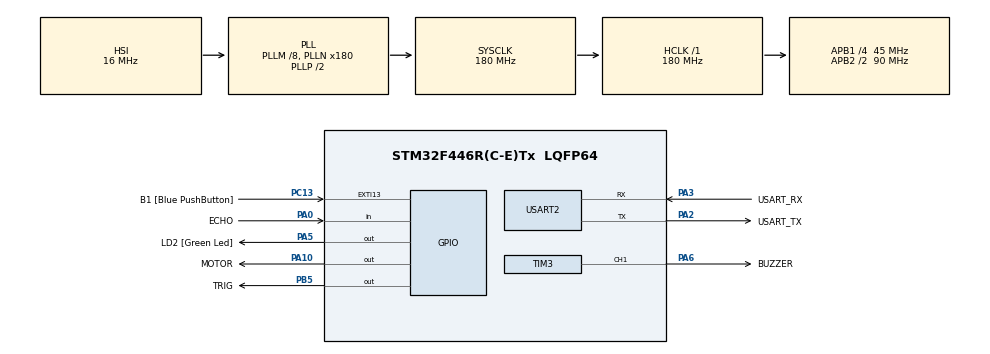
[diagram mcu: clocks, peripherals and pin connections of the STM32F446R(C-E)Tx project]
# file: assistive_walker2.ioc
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FREERTOS.Tasks01=defaultTask,24,128,StartDefaultTask,Default,NULL,Dynamic,NULL,NULL
Mcu.Family=STM32F4
Mcu.Name=STM32F446R(C-E)Tx
Mcu.Package=LQFP64
NVIC.PriorityGroup=NVIC_PRIORITYGROUP_4
NVIC.TIM6_DAC_IRQn=true\:15\:0\:false\:false\:true\:false\:false\:true\:true
NVIC.TimeBase=TIM6_DAC_IRQn
NVIC.TimeBaseIP=TIM6
PA0-WKUP.GPIO_Label=ECHO
PA0-WKUP.Signal=GPIO_Input
PA10.GPIO_Label=MOTOR
PA10.Signal=GPIO_Output
PA13.GPIO_Label=TMS
PA13.Mode=Serial_Wire
PA13.Signal=SYS_JTMS-SWDIO
PA14.GPIO_Label=TCK
PA14.Mode=Serial_Wire
PA14.Signal=SYS_JTCK-SWCLK
PA2.GPIO_Label=USART_TX
PA2.Mode=Asynchronous
PA2.Signal=USART2_TX
PA3.GPIO_Label=USART_RX
PA3.Mode=Asynchronous
PA3.Signal=USART2_RX
PA5.GPIO_Label=LD2 [Green Led]
PA5.Signal=GPIO_Output
PA6.GPIO_Label=BUZZER
PA6.Signal=S_TIM3_CH1
PB3.GPIO_Label=SWO
PB3.Signal=SYS_JTDO-SWO
PB5.GPIO_Label=TRIG
PB5.Signal=GPIO_Output
PC13.GPIO_Label=B1 [Blue PushButton]
PC13.GPIO_ModeDefaultEXTI=GPIO_MODE_IT_FALLING
PC13.Signal=GPXTI13
PC14-OSC32_IN.Mode=LSE-External-Oscillator
PC14-OSC32_IN.Signal=RCC_OSC32_IN
PC15-OSC32_OUT.Mode=LSE-External-Oscillator
PC15-OSC32_OUT.Signal=RCC_OSC32_OUT
PH0-OSC_IN.Mode=HSE-External-Oscillator
PH0-OSC_IN.Signal=RCC_OSC_IN
PH1-OSC_OUT.Mode=HSE-External-Oscillator
PH1-OSC_OUT.Signal=RCC_OSC_OUT
ProjectManager.HeapSize=0x200
ProjectManager.StackSize=0x400
ProjectManager.TargetToolchain=STM32CubeIDE
RCC.48MHZClocksFreq_Value=84000000
RCC.AHBFreq_Value=180000000
RCC.APB1CLKDivider=RCC_HCLK_DIV4
RCC.APB1Freq_Value=45000000
RCC.APB1TimFreq_Value=90000000
RCC.APB2CLKDivider=RCC_HCLK_DIV2
RCC.APB2Freq_Value=90000000
RCC.APB2TimFreq_Value=180000000
RCC.CortexFreq_Value=180000000
RCC.FLatency-AdvancedSettings=FLASH_LATENCY_5
RCC.HCLKFreq_Value=180000000
RCC.HSE_VALUE=8000000
RCC.HSI_VALUE=16000000
RCC.PLLM=8
RCC.PLLN=180
RCC.SYSCLKFreq_VALUE=180000000
RCC.SYSCLKSource=RCC_SYSCLKSOURCE_PLLCLK
RCC.USBFreq_Value=180000000
RCC.VCOOutputFreq_Value=360000000
SH.S_TIM3_CH1.0=TIM3_CH1,PWM Generation1 CH1
TIM3.Channel-PWM\ Generation1\ CH1=TIM_CHANNEL_1
TIM3.Period=499
TIM3.Prescaler=89
TIM3.Pulse-PWM\ Generation1\ CH1=250
USART2.VirtualMode=VM_ASYNC
VP_FREERTOS_VS_CMSIS_V2.Mode=CMSIS_V2
VP_IWDG_VS_IWDG.Mode=IWDG_Activate
VP_SYS_VS_tim6.Mode=TIM6
board=NUCLEO-F446RE

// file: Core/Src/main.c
/* USER CODE BEGIN Header */
/**
  ******************************************************************************
  * @file           : main.c
  * @brief          : Main program body
  ******************************************************************************
  * @attention
  *
  * Copyright (c) 2026 STMicroelectronics.
  * All rights reserved.
  *
  * This software is licensed under terms that can be found in the LICENSE file
  * in the root directory of this software component.
  * If no LICENSE file comes with this software, it is provided AS-IS.
  *
  ******************************************************************************
  */
/* USER CODE END Header */
#include "main.h"
#include "cmsis_os.h"

IWDG_HandleTypeDef hiwdg;

TIM_HandleTypeDef htim3;

UART_HandleTypeDef huart2;

/* Definitions for defaultTask */
osThreadId_t defaultTaskHandle;
const osThreadAttr_t defaultTask_attributes = {
  .name = "defaultTask",
  .stack_size = 128 * 4,
  .priority = (osPriority_t) osPriorityNormal,
};

void SystemClock_Config(void);
static void MX_GPIO_Init(void);
static void MX_USART2_UART_Init(void);
static void MX_TIM3_Init(void);
static void MX_IWDG_Init(void);
void StartDefaultTask(void *argument);

int main(void)
{

  /* MCU Configuration--------------------------------------------------------*/

  /* Reset of all peripherals, Initializes the Flash interface and the Systick. */
  HAL_Init();

  /* Configure the system clock */
  SystemClock_Config();

  /* Initialize all configured peripherals */
  MX_GPIO_Init();
  MX_USART2_UART_Init();
  MX_TIM3_Init();
  MX_IWDG_Init();

  /* Init scheduler */
  osKernelInitialize();

  /* Create the thread(s) */
  /* creation of defaultTask */
  defaultTaskHandle = osThreadNew(StartDefaultTask, NULL, &defaultTask_attributes);

  /* Start scheduler */
  osKernelStart();

  /* We should never get here as control is now taken by the scheduler */

  /* Infinite loop */
  while (1)
  {

  }
}

void SystemClock_Config(void)
{
  RCC_OscInitTypeDef RCC_OscInitStruct = {0};
  RCC_ClkInitTypeDef RCC_ClkInitStruct = {0};

  /** Configure the main internal regulator output voltage
  */
  __HAL_RCC_PWR_CLK_ENABLE();
  __HAL_PWR_VOLTAGESCALING_CONFIG(PWR_REGULATOR_VOLTAGE_SCALE1);

  /** Initializes the RCC Oscillators according to the specified parameters
  * in the RCC_OscInitTypeDef structure.
  */
  RCC_OscInitStruct.OscillatorType = RCC_OSCILLATORTYPE_HSI|RCC_OSCILLATORTYPE_LSI;
  RCC_OscInitStruct.HSIState = RCC_HSI_ON;
  RCC_OscInitStruct.HSICalibrationValue = RCC_HSICALIBRATION_DEFAULT;
  RCC_OscInitStruct.LSIState = RCC_LSI_ON;
  RCC_OscInitStruct.PLL.PLLState = RCC_PLL_ON;
  RCC_OscInitStruct.PLL.PLLSource = RCC_PLLSOURCE_HSI;
  RCC_OscInitStruct.PLL.PLLM = 8;
  RCC_OscInitStruct.PLL.PLLN = 180;
  RCC_OscInitStruct.PLL.PLLP = RCC_PLLP_DIV2;
  RCC_OscInitStruct.PLL.PLLQ = 2;
  RCC_OscInitStruct.PLL.PLLR = 2;
  if (HAL_RCC_OscConfig(&RCC_OscInitStruct) != HAL_OK)
  {
    Error_Handler();
  }

  /** Activate the Over-Drive mode
  */
  if (HAL_PWREx_EnableOverDrive() != HAL_OK)
  {
    Error_Handler();
  }

  /** Initializes the CPU, AHB and APB buses clocks
  */
  RCC_ClkInitStruct.ClockType = RCC_CLOCKTYPE_HCLK|RCC_CLOCKTYPE_SYSCLK
                              |RCC_CLOCKTYPE_PCLK1|RCC_CLOCKTYPE_PCLK2;
  RCC_ClkInitStruct.SYSCLKSource = RCC_SYSCLKSOURCE_PLLCLK;
  RCC_ClkInitStruct.AHBCLKDivider = RCC_SYSCLK_DIV1;
  RCC_ClkInitStruct.APB1CLKDivider = RCC_HCLK_DIV4;
  RCC_ClkInitStruct.APB2CLKDivider = RCC_HCLK_DIV2;

  if (HAL_RCC_ClockConfig(&RCC_ClkInitStruct, FLASH_LATENCY_5) != HAL_OK)
  {
    Error_Handler();
  }
}

static void MX_IWDG_Init(void)
{

  hiwdg.Instance = IWDG;
  hiwdg.Init.Prescaler = IWDG_PRESCALER_4;
  hiwdg.Init.Reload = 4095;
  if (HAL_IWDG_Init(&hiwdg) != HAL_OK)
  {
    Error_Handler();
  }

}

static void MX_TIM3_Init(void)
{

  TIM_MasterConfigTypeDef sMasterConfig = {0};
  TIM_OC_InitTypeDef sConfigOC = {0};

  htim3.Instance = TIM3;
  htim3.Init.Prescaler = 89;
  htim3.Init.CounterMode = TIM_COUNTERMODE_UP;
  htim3.Init.Period = 499;
  htim3.Init.ClockDivision = TIM_CLOCKDIVISION_DIV1;
  htim3.Init.AutoReloadPreload = TIM_AUTORELOAD_PRELOAD_DISABLE;
  if (HAL_TIM_PWM_Init(&htim3) != HAL_OK)
  {
    Error_Handler();
  }
  sMasterConfig.MasterOutputTrigger = TIM_TRGO_RESET;
  sMasterConfig.MasterSlaveMode = TIM_MASTERSLAVEMODE_DISABLE;
  if (HAL_TIMEx_MasterConfigSynchronization(&htim3, &sMasterConfig) != HAL_OK)
  {
    Error_Handler();
  }
  sConfigOC.OCMode = TIM_OCMODE_PWM1;
  sConfigOC.Pulse = 250;
  sConfigOC.OCPolarity = TIM_OCPOLARITY_HIGH;
  sConfigOC.OCFastMode = TIM_OCFAST_DISABLE;
  if (HAL_TIM_PWM_ConfigChannel(&htim3, &sConfigOC, TIM_CHANNEL_1) != HAL_OK)
  {
    Error_Handler();
  }
  HAL_TIM_MspPostInit(&htim3);

}

static void MX_USART2_UART_Init(void)
{

  huart2.Instance = USART2;
  huart2.Init.BaudRate = 115200;
  huart2.Init.WordLength = UART_WORDLENGTH_8B;
  huart2.Init.StopBits = UART_STOPBITS_1;
  huart2.Init.Parity = UART_PARITY_NONE;
  huart2.Init.Mode = UART_MODE_TX_RX;
  huart2.Init.HwFlowCtl = UART_HWCONTROL_NONE;
  huart2.Init.OverSampling = UART_OVERSAMPLING_16;
  if (HAL_UART_Init(&huart2) != HAL_OK)
  {
    Error_Handler();
  }

}

static void MX_GPIO_Init(void)
{
  GPIO_InitTypeDef GPIO_InitStruct = {0};

  /* GPIO Ports Clock Enable */
  __HAL_RCC_GPIOC_CLK_ENABLE();
  __HAL_RCC_GPIOH_CLK_ENABLE();
  __HAL_RCC_GPIOA_CLK_ENABLE();
  __HAL_RCC_GPIOB_CLK_ENABLE();

  /*Configure GPIO pin Output Level */
  HAL_GPIO_WritePin(GPIOA, LD2_Pin|MOTOR_Pin, GPIO_PIN_RESET);

  /*Configure GPIO pin Output Level */
  HAL_GPIO_WritePin(TRIG_GPIO_Port, TRIG_Pin, GPIO_PIN_RESET);

  /*Configure GPIO pin : B1_Pin */
  GPIO_InitStruct.Pin = B1_Pin;
  GPIO_InitStruct.Mode = GPIO_MODE_IT_FALLING;
  GPIO_InitStruct.Pull = GPIO_NOPULL;
  HAL_GPIO_Init(B1_GPIO_Port, &GPIO_InitStruct);

  /*Configure GPIO pin : ECHO_Pin */
  GPIO_InitStruct.Pin = ECHO_Pin;
  GPIO_InitStruct.Mode = GPIO_MODE_INPUT;
  GPIO_InitStruct.Pull = GPIO_NOPULL;
  HAL_GPIO_Init(ECHO_GPIO_Port, &GPIO_InitStruct);

  /*Configure GPIO pins : LD2_Pin MOTOR_Pin */
  GPIO_InitStruct.Pin = LD2_Pin|MOTOR_Pin;
  GPIO_InitStruct.Mode = GPIO_MODE_OUTPUT_PP;
  GPIO_InitStruct.Pull = GPIO_NOPULL;
  GPIO_InitStruct.Speed = GPIO_SPEED_FREQ_LOW;
  HAL_GPIO_Init(GPIOA, &GPIO_InitStruct);

  /*Configure GPIO pin : TRIG_Pin */
  GPIO_InitStruct.Pin = TRIG_Pin;
  GPIO_InitStruct.Mode = GPIO_MODE_OUTPUT_PP;
  GPIO_InitStruct.Pull = GPIO_NOPULL;
  GPIO_InitStruct.Speed = GPIO_SPEED_FREQ_LOW;
  HAL_GPIO_Init(TRIG_GPIO_Port, &GPIO_InitStruct);

  /* USER CODE BEGIN MX_GPIO_Init_2 */
  GPIO_InitStruct.Pin = ECHO_Pin;
  GPIO_InitStruct.Mode = GPIO_MODE_IT_RISING_FALLING;
  GPIO_InitStruct.Pull = GPIO_NOPULL;
  HAL_GPIO_Init(ECHO_GPIO_Port, &GPIO_InitStruct);

  HAL_NVIC_SetPriority(EXTI0_IRQn, 0, 0);
  HAL_NVIC_EnableIRQ(EXTI0_IRQn);
  /* USER CODE END MX_GPIO_Init_2 */
}

void StartDefaultTask(void *argument)
{
  for(;;)
  {
    osDelay(1);
  }
}

void HAL_TIM_PeriodElapsedCallback(TIM_HandleTypeDef *htim)
{
  if (htim->Instance == TIM6)
  {
    HAL_IncTick();
  }
}

void Error_Handler(void)
{
  __disable_irq();
  while (1)
  {
  }
}
